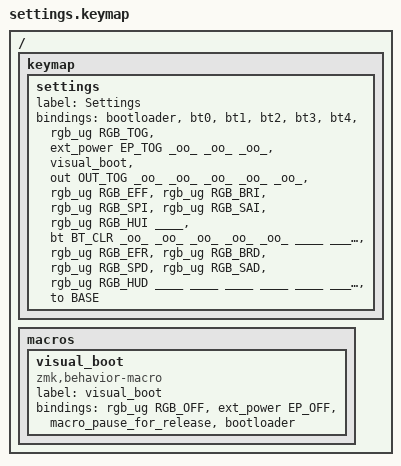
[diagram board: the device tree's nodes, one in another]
#define bt0 bt BT_SEL 0
#define bt1 bt BT_SEL 1
#define bt2 bt BT_SEL 2
#define bt3 bt BT_SEL 3
#define bt4 bt BT_SEL 4

/ {
	keymap {
		settings {
			label = "Settings";
			bindings = <
//                ╭───────────────┬──────┬──────┬──────┬──────┬──────╮                           ╭──────────────┬───────────────────┬───────────┬─────────┬─────────┬──────╮
//                │     boot      │ bt 0 │ bt 1 │ bt 2 │ bt 3 │ bt 4 │                           │ Toggle light │ &ext_power EP_TOG │    ---    │   ---   │   ---   │ boot │
//                ├───────────────┼──────┼──────┼──────┼──────┼──────┤                           ├──────────────┼───────────────────┼───────────┼─────────┼─────────┼──────┤
//                │ Toggle Output │ ---  │ ---  │ ---  │ ---  │ ---  │                           │   Next Eff   │      Inc Bri      │ Inc Speed │ Inc Sat │ Inc Hue │      │
//                ├───────────────┼──────┼──────┼──────┼──────┼──────┼─────┬─────╮   ╭─────┬─────┼──────────────┼───────────────────┼───────────┼─────────┼─────────┼──────┤
//                │    Clear BT   │ ---  │ ---  │ ---  │ ---  │ ---  │     │     │   │     │     │   Prev Eff   │      Dec Bri      │ Dec Speed │ Dec Sat │ Dec Hue │      │
//                ╰───────────────┴──────┴──────┼──────┼──────┼──────┼─────┼─────┤   ├─────┼─────┼──────────────┼───────────────────┼───────────┼─────────┴─────────┴──────╯
//                                              │      │      │      │     │     │   │     │     │              │                   │ &to BASE  │                           
//                                              ╰──────┴──────┴──────┴─────┴─────╯   ╰─────┴─────┴──────────────┴───────────────────┴───────────╯                           
              &bootloader    &bt0   &bt1   &bt2   &bt3   &bt4                                   &rgb_ug RGB_TOG   &ext_power EP_TOG   _oo_              _oo_              _oo_              &visual_boot
              &out OUT_TOG   _oo_   _oo_   _oo_   _oo_   _oo_                                   &rgb_ug RGB_EFF   &rgb_ug RGB_BRI     &rgb_ug RGB_SPI   &rgb_ug RGB_SAI   &rgb_ug RGB_HUI   ____        
              &bt BT_CLR     _oo_   _oo_   _oo_   _oo_   _oo_   ____   ____       ____   ____   &rgb_ug RGB_EFR   &rgb_ug RGB_BRD     &rgb_ug RGB_SPD   &rgb_ug RGB_SAD   &rgb_ug RGB_HUD   ____        
                                           ____   ____   ____   ____   ____       ____   ____   ____              ____                &to BASE                                                          
			>;
		};
	};
	macros {
		visual_boot: visual_boot {
            compatible = "zmk,behavior-macro";
            label = "visual_boot";
            #binding-cells = <0>;
			// wait-ms = <0>;
            bindings =
                <&rgb_ug RGB_OFF>,
                <&ext_power EP_OFF>,
                <&macro_pause_for_release>,
                <&bootloader>;
        };
    };
};
